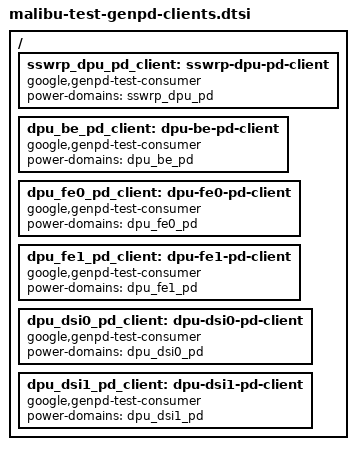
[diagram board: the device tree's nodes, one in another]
// SPDX-License-Identifier: GPL-2.0 OR BSD-3-Clause

/ {
	// DPU genpd test clients
	sswrp_dpu_pd_client: sswrp-dpu-pd-client {
		compatible = "google,genpd-test-consumer";
		power-domains = <&sswrp_dpu_pd>;
	};

	dpu_be_pd_client: dpu-be-pd-client {
		compatible = "google,genpd-test-consumer";
		power-domains = <&dpu_be_pd>;
	};

	dpu_fe0_pd_client: dpu-fe0-pd-client {
		compatible = "google,genpd-test-consumer";
		power-domains = <&dpu_fe0_pd>;
	};

	dpu_fe1_pd_client: dpu-fe1-pd-client {
		compatible = "google,genpd-test-consumer";
		power-domains = <&dpu_fe1_pd>;
	};

	dpu_dsi0_pd_client: dpu-dsi0-pd-client {
		compatible = "google,genpd-test-consumer";
		power-domains = <&dpu_dsi0_pd>;
	};

	dpu_dsi1_pd_client: dpu-dsi1-pd-client {
		compatible = "google,genpd-test-consumer";
		power-domains = <&dpu_dsi1_pd>;
	};
};
